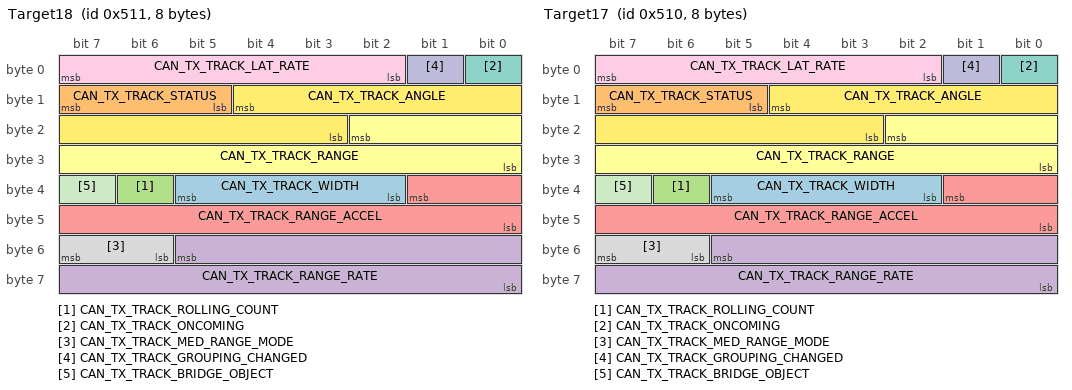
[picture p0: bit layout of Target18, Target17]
BO_ 1297 Target18: 8 Vector__XXX
 SG_ CAN_TX_TRACK_WIDTH : 37|4@0+ (0.5,0) [0|7.5] "" Vector__XXX
 SG_ CAN_TX_TRACK_STATUS : 15|3@0+ (1,0) [0|7] "" Vector__XXX
 SG_ CAN_TX_TRACK_ROLLING_COUNT : 38|1@0+ (1,0) [0|1] "" Vector__XXX
 SG_ CAN_TX_TRACK_RANGE_RATE : 53|14@0- (0.01,0) [-81.92|81.91] "m/s" Vector__XXX
 SG_ CAN_TX_TRACK_RANGE_ACCEL : 33|10@0- (0.05,0) [-25.6|25.55] "m/s^2" Vector__XXX
 SG_ CAN_TX_TRACK_RANGE : 18|11@0+ (0.1,0) [0|204.7] "m" Vector__XXX
 SG_ CAN_TX_TRACK_ONCOMING : 0|1@0+ (1,0) [0|1] "" Vector__XXX
 SG_ CAN_TX_TRACK_MED_RANGE_MODE : 55|2@0+ (1,0) [0|3] "" Vector__XXX
 SG_ CAN_TX_TRACK_LAT_RATE : 7|6@0- (0.25,0) [-8|7.75] "" Vector__XXX
 SG_ CAN_TX_TRACK_GROUPING_CHANGED : 1|1@0+ (1,0) [0|1] "" Vector__XXX
 SG_ CAN_TX_TRACK_BRIDGE_OBJECT : 39|1@0+ (1,0) [0|1] "" Vector__XXX
 SG_ CAN_TX_TRACK_ANGLE : 12|10@0- (0.1,0) [-51.2|51.1] "" Vector__XXX

BO_ 1296 Target17: 8 Vector__XXX
 SG_ CAN_TX_TRACK_WIDTH : 37|4@0+ (0.5,0) [0|7.5] "" Vector__XXX
 SG_ CAN_TX_TRACK_STATUS : 15|3@0+ (1,0) [0|7] "" Vector__XXX
 SG_ CAN_TX_TRACK_ROLLING_COUNT : 38|1@0+ (1,0) [0|1] "" Vector__XXX
 SG_ CAN_TX_TRACK_RANGE_RATE : 53|14@0- (0.01,0) [-81.92|81.91] "m/s" Vector__XXX
 SG_ CAN_TX_TRACK_RANGE_ACCEL : 33|10@0- (0.05,0) [-25.6|25.55] "m/s^2" Vector__XXX
 SG_ CAN_TX_TRACK_RANGE : 18|11@0+ (0.1,0) [0|204.7] "m" Vector__XXX
 SG_ CAN_TX_TRACK_ONCOMING : 0|1@0+ (1,0) [0|1] "" Vector__XXX
 SG_ CAN_TX_TRACK_MED_RANGE_MODE : 55|2@0+ (1,0) [0|3] "" Vector__XXX
 SG_ CAN_TX_TRACK_LAT_RATE : 7|6@0- (0.25,0) [-8|7.75] "" Vector__XXX
 SG_ CAN_TX_TRACK_GROUPING_CHANGED : 1|1@0+ (1,0) [0|1] "" Vector__XXX
 SG_ CAN_TX_TRACK_BRIDGE_OBJECT : 39|1@0+ (1,0) [0|1] "" Vector__XXX
 SG_ CAN_TX_TRACK_ANGLE : 12|10@0- (0.1,0) [-51.2|51.1] "" Vector__XXX
